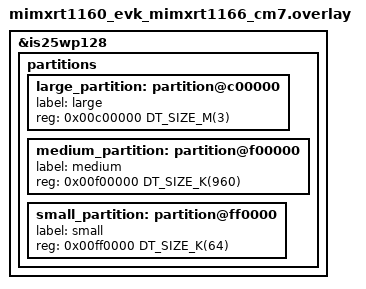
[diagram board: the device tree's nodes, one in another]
/*
 * Copyright 2025 NXP
 *
 * SPDX-License-Identifier: Apache-2.0
 */

/delete-node/ &storage_partition;

&is25wp128 {
	partitions {
		large_partition: partition@c00000 {
			label = "large";
			reg = <0x00c00000 DT_SIZE_M(3)>;
		};

		medium_partition: partition@f00000 {
			label = "medium";
			reg = <0x00f00000 DT_SIZE_K(960)>;
		};

		small_partition: partition@ff0000 {
			label = "small";
			reg = <0x00ff0000 DT_SIZE_K(64)>;
		};
	};
};
